# AC33GA256 register map
Vendor: ABOV Semiconductor Co., Ltd.; File version: 0.1
CPU: CM3 r1p0, little endian, no MPU, no FPU, 3 interrupt priority bits
Registers are 32-bit, read-write, reset 0x0 unless marked. A register's access mark holds for its fields unless they carry their own. Offsets are from the block's base; [hi:lo] are bit positions; {n}, {i} and the like mark numbered series.

## UART0 — UNIVERSAL ASYNCHRONOUS RECEIVER/TRANSMITTER
Base 0x40000B00
Same registers: UART1 0x40000B40, UART2 0x40000B80, UART3 0x40000BC0
0x00 RBR_THR_DLL
  [7:0] RBR_THR_DLL
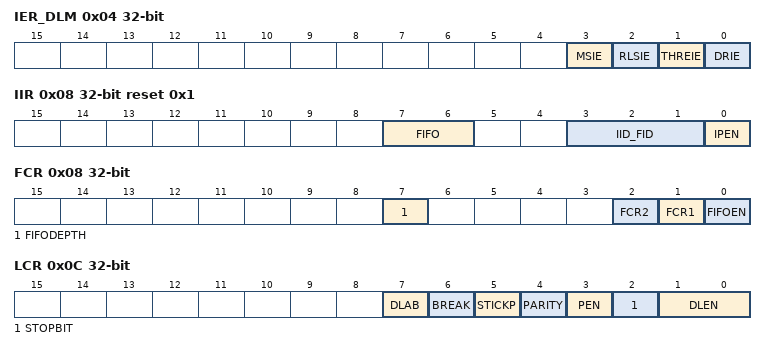
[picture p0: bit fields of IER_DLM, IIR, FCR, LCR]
0x04 IER_DLM — UART Interrupt Enable Register
  [3] MSIE — not used
  [2] RLSIE — receiver line status interrupt enable
  [1] THREIE — Transmit holding register empty interrupt enable
  [0] DRIE — Data Ready Interrupt Enable/Disable
0x08 IIR ro reset 0x1 — UART Interrupt ID Register
  [7:6] FIFO — Current UART operation FIFO mode
  [3:1] IID_FID — Interrupt source ID
  [0] IPEN — Interrupt pending bit
0x08 FCR wo — FIFO Control Register
  [7] FIFODEPTH — Receive FIFO trigger level
  [2] FCR2 — Initialize transmit FIFO
  [1] FCR1 — Initialize receive FIFO
  [0] FIFOEN — Enable transmit/receive FIFO
0x0C LCR — UART Line Control Register
  [7] DLAB — Norma Transmission-Divisor Latch Access Mode
  [6] BREAK — Normal Transmission-Send Break
  [5] STICKP — Stick Parity as L-H
  [4] PARITY — OddEven Parity
  [3] PEN — Enable Parity
  [2] STOPBIT — 1-(1.5,2) stop bits
  [1:0] DLEN — Data length in one transfer word
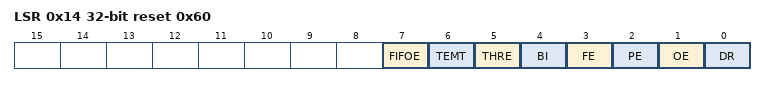
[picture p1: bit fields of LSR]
0x14 LSR reset 0x60 — UART Line Status Register
  [7] FIFOE ro — FIFO has invalid data
  [6] TEMT ro — Transmitter Empty
  [5] THRE ro — THR Empty
  [4] BI ro — break condition indication bit
  [3] FE ro — frame error
  [2] PE ro — parity error
  [1] OE ro — overrun error
  [0] DR ro — Data recevied
0x1C SCR — UART Scratch Register
  [7:0] SCR — This register is used to store a data temporarily by software programmer

## SPI0 — SERIAL PERIPHERAL INTERFACE
Base 0x40000800
Same registers: SPI1 0x40000820
0x00 RDR_TDR — SPI n Receive Data Register
  [15:0] RDR_TDR — Data
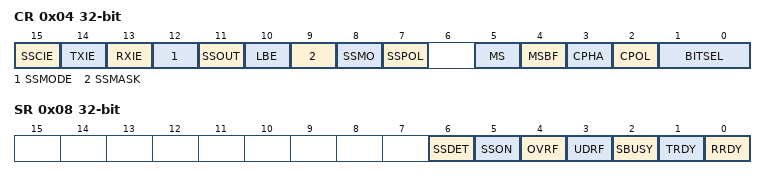
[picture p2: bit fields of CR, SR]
0x04 CR — SPI n Control Register
  [15] SSCIE — SSn Edge Chagne Interrupt enable bit
  [14] TXIE — Transmit interrupt enable bit
  [13] RXIE — Receive interrupt enable bit
  [12] SSMODE — SS Auto/Manual Output select bit
  [11] SSOUT — SS output signal select bit
  [10] LBE — Loop-back mode select bit in master mode
  [9] SSMASK — SS Signal masking bit in slave mode
  [8] SSMO — SS output signal select bit
  [7] SSPOL — SS Signal polarity select bit
  [5] MS — master/slaver select bit
  [4] MSBF — MSB/LSB transmit select bit
  [3] CPHA — SPI clock phase bit
  [2] CPOL — SPI clock polarity bit
  [1:0] BITSEL — Transmit/receive Data bits select bit
0x08 SR — SPI n Status Register
  [6] SSDET — The rising edge of SS detect flag
  [5] SSON ro — SS signal status flag
  [4] OVRF — receive overrun error flag
  [3] UDRF — transmit underrun error flag
  [2] SBUSY ro — transmit/receive operation flag
  [1] TRDY ro — Transmit buffer empty flag
  [0] RRDY ro — receive buffer ready flag
0x0C BR — SPI n Baud Rate Register
  [7:0] BR — buadrate
0x10 EN — SPI n Enable register
  [0] ENABLE — SPI ENABLE bit

## ADC — 12-BIT A/D CONVERTER
Base 0x40000E00
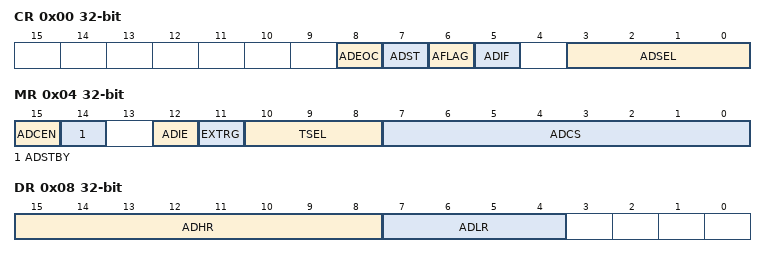
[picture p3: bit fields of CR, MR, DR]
0x00 CR — ADC Control Register
  [8] ADEOC — A/D Conversion Status (Read/Write)
  [7] ADST — A/D Conversion Start
  [6] AFLAG — A/D Conversion Status Flag (Read-Only)
  [5] ADIF — A/D Converter interrupt Flag
  [3:0] ADSEL — Select ADC input channel
0x04 MR — ADC Mode Register
  [15] ADCEN — Select ADC Enable
  [14] ADSTBY — Select ADC Stand-by mode
  [12] ADIE — Select End-of-Conversion interrupt
  [11] EXTRG — Select external trigger condition for start conversion
  [10:8] TSEL — SOC trigger source
  [7:0] ADCS — Select A/D conversion clock
0x08 DR ro (reset mask 0xFF) — A/D Data Register
  [15:8] ADHR — Upper byte of A/D conversion data
  [7:4] ADLR — Lower byte of A/D conversion data

## FMC — INTERNAL FLASH MEMORY
Base 0x40000100
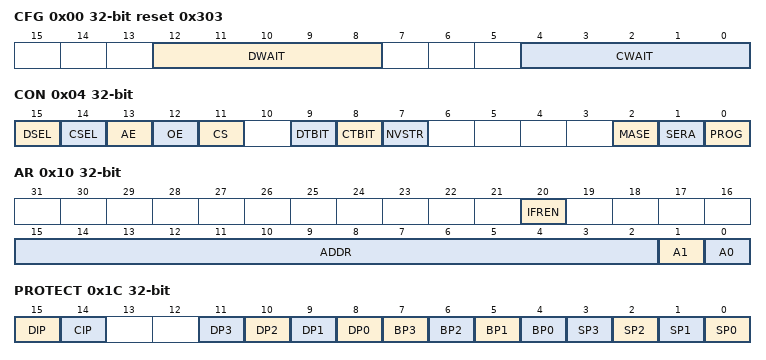
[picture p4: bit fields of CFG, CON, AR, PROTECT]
0x00 CFG reset 0x303 — Flash Memory Configuration Register
  [12:8] DWAIT — Wait value of data flash memory
  [4:0] CWAIT — Wait value of code flash memory
0x04 CON — Flash Memory Control Register
  [15] DSEL — Select Data Flash for PGMERASE
  [14] CSEL — Select Code Flash for PGMERASE
  [13] AE — Latch Address for PGMERASE
  [12] OE — Code Flash PGM mode
  [11] CS — Select FlashROM for PGMERASE
  [9] DTBIT ro — Data Flash PGM ERASE Status Flag
  [8] CTBIT ro — Code Flash PGM ERASE Status Flag
  [7] NVSTR — PGM ERASE Start
  [2] MASE — Select Code or Data Flash Macro Erase
  [1] SERA — Select Code or Data Flash Sector Erase
  [0] PROG — Select Code or Data Flash for PGM
0x08 ODR — Flash Memory Output Data Register
  [31:0] ODR — Output Data to the Flash Memories
0x0C IDR ro — Flash Memory Input Data Register
  [31:0] IDR — Input Data from the Flash Memories
0x10 AR — Flash Memory Address Register
  [20] IFREN — Always 0 (prohibited to write 1)
  [15:2] ADDR — Flash Memory Address Value
  [1] A1 — Address A1 for Data Flash Memory
  [0] A0 — Address A0 for Data Flash Memory
0x1C PROTECT — Flash Memory Protection Register
  [15] DIP — Always 0
  [14] CIP — Always 0
  [n+8] DP{n} (n=0..3) — Protection bit of the Data Flash 8KB #{n}
  [7] BP3 — Protection bit from 0x0003_0000 to 0x0003_FFFF
  [6] BP2 — Protection bit from 0x0002_0000 to 0x0002_FFFF
  [5] BP1 — Protection bit from 0x0001_0000 to 0x0001_FFFF
  [4] BP0 — Protection bit from 0x0000_4000 to 0x0000_FFFF
  [n] SP{n} (n=0..3) — Protection bit from 0x0000_{1000n:04} to 0x0000_{n}FFF

## MEMCR — Memory Control Register
Base 0x400000E0
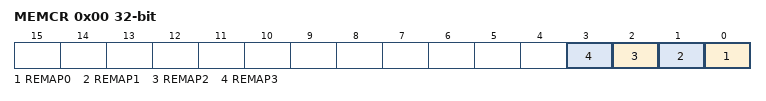
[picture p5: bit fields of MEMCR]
0x00 MEMCR — Memory Control Register
  [n] REMAP{n} (n=0..3) — Remap {0x0+0x1000*n} ~ {0xFFF+0x1000*n} Area (Area {n})
